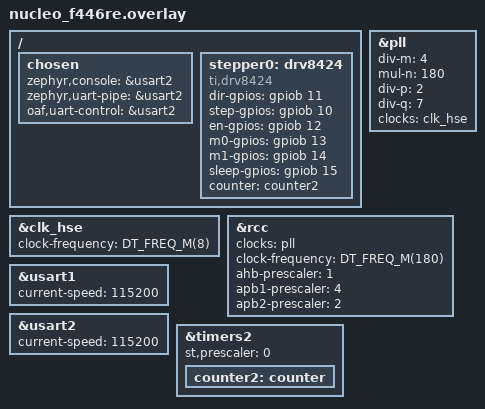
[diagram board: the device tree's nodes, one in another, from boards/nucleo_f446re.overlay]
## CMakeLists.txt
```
# SPDX-License-Identifier: Apache-2.0

cmake_minimum_required(VERSION 3.20.0)

list(APPEND EXTRA_CONF_FILE 
    "logging.conf"
)

find_package(Zephyr REQUIRED HINTS $ENV{ZEPHYR_BASE})
project(OpenAstroFirmware)

add_subdirectory(lib)

zephyr_syscall_include_directories(include)
zephyr_include_directories(include)

# print the value of LIB_INCLUDE_DIRS
# message(STATUS "LIB_INCLUDE_DIRS: ${LIB_INCLUDE_DIRS}")

include(CMakePrintHelpers)
cmake_print_variables(PROJECT_SOURCE_DIR)

# Add the source files to the target
file(GLOB_RECURSE APP_SOURCES "src/*.cpp" "src/*.c")
target_sources(app PRIVATE ${APP_SOURCES})
```

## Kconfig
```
module = FIRMWARE
module-str = firmware
source "subsys/logging/Kconfig.template.log_config"

rsource "lib/Kconfig"

rsource "src/mount/Kconfig"
rsource "src/processor/lx200/Kconfig"

menu "Zephyr"
source "Kconfig.zephyr"
endmenu
```

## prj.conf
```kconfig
# Disable zephyr log message at the beginning of the boot process
# CONFIG_BOOT_BANNER=n

# C++ support
CONFIG_CPP=y
CONFIG_STD_CPP20=y
CONFIG_REQUIRES_FULL_LIBCPP=y

# GPIO support
CONFIG_GPIO=y

# CONFIG_RING_BUFFER=y
# CONFIG_LX200=y

# CONFIG_TIMING_FUNCTIONS=y
CONFIG_MAIN_THREAD_PRIORITY=5

CONFIG_MAIN_STACK_SIZE=4096

# Stepper
CONFIG_POLL=y
CONFIG_COUNTER=y
CONFIG_STEPPER=y
CONFIG_STEP_DIR_STEPPER_COUNTER_TIMING=y

CONFIG_HEAP_MEM_POOL_SIZE=4096

# Thread analyzer
# CONFIG_THREAD_ANALYZER=y
# CONFIG_THREAD_ANALYZER_USE_PRINTK=y 
# CONFIG_THREAD_ANALYZER_AUTO=y
# CONFIG_THREAD_ANALYZER_AUTO_INTERVAL=5
```

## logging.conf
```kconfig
# Serial console
CONFIG_SERIAL=y
CONFIG_CONSOLE=y
CONFIG_CONSOLE_SUBSYS=y
CONFIG_CONSOLE_GETCHAR=y
CONFIG_CONSOLE_GETCHAR_BUFSIZE=64
CONFIG_CONSOLE_PUTCHAR_BUFSIZE=512
CONFIG_STDOUT_CONSOLE=y

# UART
CONFIG_UART_CONSOLE=y
CONFIG_UART_INTERRUPT_DRIVEN=y
CONFIG_UART_LINE_CTRL=y
CONFIG_UART_CONSOLE_LOG_LEVEL_DBG=y

CONFIG_LOG=y
CONFIG_LOG_BACKEND_UART=y
# CONFIG_LOG_MODE_DEFERRED=y
CONFIG_LOG_MODE_IMMEDIATE=y

# Enables runtime filtering for logging.
# This allows the logging level to be changed at runtime,
# providing flexibility for debugging and monitoring.
# CONFIG_LOG_RUNTIME_FILTERING=y
# CONFIG_LOG_BUFFER_SIZE=4096
# CONFIG_LOG_PRINTK=y
# CONFIG_LOG_PROCESS_TRIGGER_THRESHOLD=0
# CONFIG_LOG_TAG_MAX_LEN=8

CONFIG_LOG_THREAD_ID_PREFIX=y

# Enable thread analyzer in the logs
# CONFIG_THREAD_ANALYZER=y
# CONFIG_THREAD_ANALYZER_USE_PRINTK=y
# CONFIG_THREAD_ANALYZER_AUTO=y
# CONFIG_THREAD_ANALYZER_AUTO_INTERVAL=5

# Enable fault handling
# CONFIG_FAULT_DUMP=2
# CONFIG_EXCEPTION_STACK_TRACE=y
# CONFIG_DEBUG_COREDUMP=y 
# CONFIG_DEBUG_COREDUMP_BACKEND_LOGGING=y
# CONFIG_DEBUG_COREDUMP_MEMORY_DUMP_MIN=y

# Set log levels
# 0 - off
# 1 - error
# 2 - warning
# 3 - info
# 4 - debug

# Default log level (including zephyr)
CONFIG_LOG_DEFAULT_LEVEL=3

# OpenAstroFirmware log level. If multiple active, highest level wins.
# CONFIG_FIRMWARE_LOG_LEVEL_OFF=y # 0
# CONFIG_FIRMWARE_LOG_LEVEL_ERR=y # 1
# CONFIG_FIRMWARE_LOG_LEVEL_WRN=y # 2
# CONFIG_FIRMWARE_LOG_LEVEL_INF=y # 3 (default)
# CONFIG_FIRMWARE_LOG_LEVEL_DBG=y # 4

# Mount log level
# CONFIG_LOG_MOUNT_LEVEL=3
```

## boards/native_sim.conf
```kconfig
CONFIG_UART_CONSOLE=y

# Enable the native POSIX UART driver backend
CONFIG_UART_NATIVE_POSIX=y

# Console (logs) will be on stdout
# CONFIG_UART_NATIVE_PTY_0_ON_STDINOUT=y
# CONFIG_NATIVE_UART_0_ON_STDINOUT=y

# Enable UART for control (e.g. lx200)
CONFIG_UART_NATIVE_POSIX_PORT_1_ENABLE=y
```

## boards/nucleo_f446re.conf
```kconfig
CONFIG_SYS_CLOCK_HW_CYCLES_PER_SEC=180000000
CONFIG_CORTEX_M_SYSTICK=y

CONFIG_UART_USE_RUNTIME_CONFIGURE=y

# CONFIG_USB_DEVICE_STACK=y
# CONFIG_USB_DEVICE_INITIALIZE_AT_BOOT=n
# CONFIG_USB_DEVICE_VID=0x1209
# CONFIG_USB_DEVICE_PID=0x0AF0
# CONFIG_USB_DEVICE_PRODUCT="OpenAstroFirmware"
# CONFIG_USB_DEVICE_MANUFACTURER="OpenAstroTech"

# CONFIG_USB_CDC_ACM=y
# CONFIG_USB_CDC_ACM_RINGBUF_SIZE=512

# CONFIG_USB_COMPOSITE_DEVICE=y

# # CONFIG_USB_DEVICE_LOG_LEVEL_INF=y
# # CONFIG_USB_DRIVER_LOG_LEVEL_INF=y
# CONFIG_USB_CDC_ACM_LOG_LEVEL_OFF=y
```

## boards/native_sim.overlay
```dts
/ {
    chosen {
        zephyr,console = &uart0;
        // zephyr,shell-uart = &usart1;
        // zephyr,uart-mcumgr = &usart1;
        // zephyr,bt-mon-uart = &usart1;
        // zephyr,bt-c2h-uart = &usart1;
        // zephyr,log-backend-uart = &usart2;

        // zephyr,shell-uart = &usart1;
        // zephyr,uart-mcumgr = &usart1;
        oaf,uart-control = &uart1;
    };

    // uart {
    //     status = "okay";
    //     compatible = "zephyr,native-tty-uart";
    //     serial-port = "/tmp/tty1_device";
    //     current-speed = <115200>;
    // };
};

&uart0 {
    status = "okay";
    current-speed = <115200>;
};

// &uart1 {
    //     status = "okay";
    //     current-speed = <115200>;
// };

// &uart1 {
    //     status = "okay";
    //     current-speed = <115200>;
// };
```

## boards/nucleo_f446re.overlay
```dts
/ {
    chosen {
        zephyr,console = &usart2;
        zephyr,uart-pipe = &usart2;
        oaf,uart-control = &usart2;
    };

    stepper0: drv8424 {
        compatible = "ti,drv8424";
        status = "okay";

        #address-cells = <1>;
		#size-cells = <0>;
		#stepper-motor-cells = <0>;

        dir-gpios = <&gpiob 11 GPIO_ACTIVE_HIGH>;
        step-gpios = <&gpiob 10 GPIO_ACTIVE_HIGH>;
        en-gpios = <&gpiob 12 GPIO_ACTIVE_HIGH>;
        m0-gpios = <&gpiob 13 GPIO_ACTIVE_HIGH>;
        m1-gpios = <&gpiob 14 GPIO_ACTIVE_HIGH>;
        sleep-gpios = <&gpiob 15 GPIO_ACTIVE_HIGH>;
    
        counter = <&counter2>;
    };
};

&clk_hse {
    clock-frequency = <DT_FREQ_M(8)>;
};

&pll {
    div-m = <4>;
    mul-n = <180>;
    div-p = <2>;
    div-q = <7>;
    clocks = <&clk_hse>;
    status = "okay";
};

&rcc {
    clocks = <&pll>;
    clock-frequency = <DT_FREQ_M(180)>;
    ahb-prescaler = <1>;
    apb1-prescaler = <4>;
    apb2-prescaler = <2>;
};

&usart1 {
    status = "okay";
    current-speed = <115200>;
};

&usart2 {
    status = "okay";
    current-speed = <115200>;
};

&timers2 {
    status = "okay";
    st,prescaler = <0>;

    counter2: counter {
        status = "okay";
    };
};
```

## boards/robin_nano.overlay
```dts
/ {
    chosen {
        // we can't use cdc acm as console because it lacks required amount of cdc acm endpoints
        zephyr,console = &usart3; 
        oaf,uart-control = &cdc_acm_uart0;
    };
};

// Configuration for the CDC ACM UART
&zephyr_udc0 {
    cdc_acm_uart0: cdc_acm_uart0 {
        compatible = "zephyr,cdc-acm-uart";
    };
};
```

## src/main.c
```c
/*
 * Copyright (c) 2016 Open-RnD Sp. z o.o.
 * Copyright (c) 2020 Nordic Semiconductor ASA
 *
 * SPDX-License-Identifier: Apache-2.0
 */

#include <zephyr/kernel.h>
#include <zephyr/device.h>
#include <zephyr/drivers/gpio.h>
#include <zephyr/sys/util.h>
#include <zephyr/sys/printk.h>
#include <inttypes.h>

#include <lx200.h>

#define SLEEP_TIME_MS 1

/*
 * Get button configuration from the devicetree sw0 alias. This is mandatory.
 */
#define SW0_NODE DT_ALIAS(sw0)
#if !DT_NODE_HAS_STATUS(SW0_NODE, okay)
#error "Unsupported board: sw0 devicetree alias is not defined"
#endif
static const struct gpio_dt_spec button = GPIO_DT_SPEC_GET_OR(SW0_NODE, gpios, {0});
static struct gpio_callback button_cb_data;

/*
 * The led0 devicetree alias is optional. If present, we'll use it
 * to turn on the LED whenever the button is pressed.
 */
static struct gpio_dt_spec led = GPIO_DT_SPEC_GET_OR(DT_ALIAS(led0), gpios, {0});

void lx200_initialize()
{
	printk("Initializing LX200\n");
}

lx200_command_handler_t lx200_command_handler = {
	.lx200_initialize = lx200_initialize,
};

void button_pressed(const struct device *dev, struct gpio_callback *cb,
					uint32_t pins)
{
	lx200_parse_command(":g+#", 4, &lx200_command_handler);
	printk("Button pressed at %" PRIu32 "\n", k_cycle_get_32());
}

int main(void)
{
	int ret;

	if (!gpio_is_ready_dt(&button))
	{
		printk("Error: button device %s is not ready\n",
			   button.port->name);
		return 0;
	}

	ret = gpio_pin_configure_dt(&button, GPIO_INPUT);
	if (ret != 0)
	{
		printk("Error %d: failed to configure %s pin %d\n",
			   ret, button.port->name, button.pin);
		return 0;
	}

	ret = gpio_pin_interrupt_configure_dt(&button,
										  GPIO_INT_EDGE_TO_ACTIVE);
	if (ret != 0)
	{
		printk("Error %d: failed to configure interrupt on %s pin %d\n",
			   ret, button.port->name, button.pin);
		return 0;
	}

	gpio_init_callback(&button_cb_data, button_pressed, BIT(button.pin));
	gpio_add_callback(button.port, &button_cb_data);
	printk("Set up button at %s pin %d\n", button.port->name, button.pin);

	if (led.port && !gpio_is_ready_dt(&led))
	{
		printk("Error %d: LED device %s is not ready; ignoring it\n",
			   ret, led.port->name);
		led.port = NULL;
	}
	if (led.port)
	{
		ret = gpio_pin_configure_dt(&led, GPIO_OUTPUT);
		if (ret != 0)
		{
			printk("Error %d: failed to configure LED device %s pin %d\n",
				   ret, led.port->name, led.pin);
			led.port = NULL;
		}
		else
		{
			printk("Set up LED at %s pin %d\n", led.port->name, led.pin);
		}
	}

	printk("Press the button\n");
	if (led.port)
	{
		while (1)
		{
			/* If we have an LED, match its state to the button's. */
			int val = gpio_pin_get_dt(&button);

			if (val >= 0)
			{
				gpio_pin_set_dt(&led, val);
			}
			k_msleep(SLEEP_TIME_MS);
		}
	}
	return 0;
}
```

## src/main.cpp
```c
/*
 * Copyright (c) 2016 Open-RnD Sp. z o.o.
 * Copyright (c) 2020 Nordic Semiconductor ASA
 *
 * SPDX-License-Identifier: Apache-2.0
 */

#include <inttypes.h>

#include <zephyr/device.h>
#include <zephyr/drivers/gpio.h>
#include <zephyr/drivers/uart.h>
#include <zephyr/kernel.h>
#include <zephyr/logging/log.h>
#include <zephyr/usb/usb_device.h>

#include "HardwareConfiguration.hpp"

#include <mount/Mount.hpp>
#include <mount/MountWorker.hpp>

#include "device/uart/InterruptUART.hpp"
#include "device/uart/PollingUART.hpp"
#include "processor/lx200/Lx200Processor.hpp"

LOG_MODULE_REGISTER(main, CONFIG_FIRMWARE_LOG_LEVEL);

Mount mount;
MountWorker mount_worker(mount);

K_MSGQ_DEFINE(uart_msgq, sizeof(uint8_t), CONFIG_LX200_MESSAGE_BUFFER_SIZE, 1);

Lx200Processor lx200_processor(&uart_msgq, mount_worker);

K_THREAD_DEFINE(
	lx200,							 // Thread identifier
	CONFIG_LX200_STACK_SIZE,		 // Stack size in bytes
	Lx200Processor::thread_function, // Entry point function for the thread
	&lx200_processor, NULL, NULL,	 // Arguments passed to the thread function (arg1, arg2, arg3)
	10,								 // Thread priority (lower number = higher priority)
	0,								 // Thread options (0 = no special options)
	0								 // Delay before starting the thread (0 = start immediately)
);

int main(void)
{
	LOG_INF("Starting OpenAstroFirmware");
	LOG_INF("Board: %s", CONFIG_BOARD);
	LOG_INF("MCU Frequency: %u Hz", sys_clock_hw_cycles_per_sec());

#ifdef CONFIG_USB_DEVICE_STACK
	if (usb_enable(NULL) != 0)
	{
		LOG_ERR("Failed to enable USB");
		return 0;
	}
#endif

	if (!device_is_ready(dt::uart_control_dev))
	{
		LOG_ERR("Control UART device not ready\n");
		return ENODEV;
	}

	struct uart_config uart_cfg;
	if (uart_config_get(dt::uart_control_dev, &uart_cfg))
	{
		LOG_ERR("Failed to get control UART configuration");
	}
	else
	{
		LOG_INF("Control UART Baud Rate: %d", uart_cfg.baudrate);
	}

	devices::uart::InterruptUART isr_uart(dt::uart_control_dev, &uart_msgq);
	isr_uart.enable();

	// devices::uart::PollingUART poll_uart(dt::uart_control_dev, &uart_msgq);
	// poll_uart.enable();

	while (1)
	{
		k_sleep(K_MSEC(1000));
	}

	return 0;
}
```

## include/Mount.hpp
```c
#pragma once

#include <zephyr/zbus/zbus.h>

class Mount {
private:
public:
    Mount();  // Constructor
    ~Mount(); // Destructor

    /**
     * @brief Initialize the mount
     */
    void initialize();

    /**
     * @brief Set the Target Dec object
     * 
     * @param d degrees
     * @param m minutes
     * @param s seconds
     */
    void setTargetDec(int d, int m, int s);

    /**
     * @brief Set the Target Ra object
     * 
     * @param h hours
     * @param m minutes
     * @param s seconds
     */
    void setTargetRa(int h, int m, int s);
};

struct MountControlCommand
{
    size_t type;
    /* data */
};

ZBUS_CHAN_DECLARE(mount_control_chan);
```

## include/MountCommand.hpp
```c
#pragma once

#include <cstddef>
#include <atomic>

enum MountCommandType
{
    InitializeMount,
    SetTargetRA
};

struct MountCommand
{
    const MountCommandType type;
    const size_t corr_id;

    MountCommand(const MountCommandType type) : corr_id(counter++), type(type) {}

    static std::atomic<unsigned long> counter;
};

struct InitializeMountCommand : public MountCommand
{
    InitializeMountCommand() : MountCommand(InitializeMount) {}
};

struct SetTargetRACommand : public MountCommand
{
    const unsigned int hh;
    const unsigned int mm;
    const unsigned int ss;

    SetTargetRACommand(unsigned int hh, unsigned int mm, unsigned int ss) : MountCommand(SetTargetRA), hh(hh), mm(mm), ss(ss) {}
};
```

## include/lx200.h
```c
#ifndef FIRMWARE_LIB_LX200_H
#define FIRMWARE_LIB_LX200_H

/* Alignment Commands */
// :Aa#    Start Telescope Automatic Alignment Sequence [LX200GPS only]
// :AL#    Sets telescope to Land alignment mode
// :AP#    Sets telescope to Polar alignment mode
// :AA#    Sets telescope the AltAz alignment mode

/* Active Backlash Compensation */
// :$BAdd# Set Altitude/Dec Antibacklash
// :$BZdd# Set Azimuth/RA Antibacklash

/* Reticule/Accessory Control */
// :B+#    Increase reticule Brightness
// :B-#    Decrease Reticule Brightness
// :B<n>#  Set Reticle flash rate to <n> (an ASCII expressed number)
// :BDn#   Set Reticule Duty flash duty cycle to <n> (an ASCII expressed digit) [LX200 GPS Only]

/* Sync Control */
// :CL#    Synchonize the telescope with the current Selenographic coordinates.
// :CM#    Synchronizes the telescope's position with the currently selected database object's coordinates.

/* Distance Bars */
// :D#     Requests a string of bars indicating the distance to the current library object.

/* Fan Command */
// :f+#    LX 16”– Turn on the tube exhaust fan, LX200GPS – Turn on power to accessor panel
// :f-#    LX 16”– Turn off tube exhaust fan, LX200GPS - Turn off power to accessory panel
// :fT#    LX200GPS – Return Optical Tube Assembly Temperature

/* Focuser Control */
// :F+#    Start Focuser moving inward (toward objective)
// :F-#    Start Focuser moving outward (away from objective)
// :FQ#    Halt Focuser Motion
// :FF#    Set Focus speed to fastest setting
// :FS#    Set Focus speed to slowest setting
// :F<n>#  Autostar & LX200GPS – set focuser speed to <n> where <n> is an ASCII digit 1..4

/* GPS/Magnetometer commands */
// :g+#    LX200GPS Only - Turn on GPS
// :g-#    LX200GPS Only - Turn off GPS
// :gps#   LX200GPS Only – Turns on NMEA GPS data stream.
// :gT#    Powers up the GPS and updates the system time from the GPS stream.

/* Get Telescope Information */
// :G0#    Get Alignment Menu Entry 0 [LX200 legacy command]
// :G1#    Get Alignment Menu Entry 0 [LX200 legacy command]
// :G2#    Get Alignment Menu Entry 0 [LX200 legacy command]
// :GA#    Get Telescope Altitude
// :Ga#    Get Local Telescope Time In 12 Hour Format
// :Gb#    Get Browse Brighter Magnitude Limit
// :GC#    Get current date.
// :Gc#    Get Calendar Format
// :GD#    Get Telescope Declination.
// :Gd#    Get Currently Selected Object/Target Declination
// :GF#    Get Find Field Diameter
// :Gf#    Get Browse Faint Magnitude Limit
// :GG#    Get UTC offset time
// :Gg#    Get Current Site Longitude
// :Gh#    Get High Limit
// :GL#    Get Local Time in 24 hour format
// :Gl#    Get Larger Size Limit
// :GM#    Get Site 1 Name
// :GN#    Get Site 2 Name
// :GO#    Get Site 3 Name
// :GP#    Get Site 4 Name
// :Go#    Get Lower Limit
// :Gq#    Get Minimum Quality For Find Operation
// :GR#    Get Telescope RA
// :Gr#    Get current/target object RA
// :GS#    Get the Sidereal Time
// :Gs#    Get Smaller Size Limit
// :GT#    Get tracking rate
// :Gt#    Get Current Site Latitude
// :GVD#   Get Telescope Firmware Date
// :GVN#   Get Telescope Firmware Number
// :GVP#   Get Telescope Product Name
// :GVT#   Get Telescope Firmware Time
// :Gy#    Get deepsky object search string
// :GZ#    Get telescope azimuth

/* Home Position Commands */
// :hS#    LX200GPS and LX 16” Seeks Home Position and stores the encoder values
// :hF#    LX200GPS and LX 16” Seeks the Home Position of the scope and sets/aligns
// :hN#    LX200GPS only: Sleep Telescope.
// :hP#    Autostar, LX200GPS and LX 16”Slew to Park Position
// :hW#    LX200 GPS Only: Wake up sleeping telescope.
// :h?#    Autostar, LX200GPS and LX 16” Query Home Status

/* Time Format Command */
// :H#     Toggle Between 24 and 12 hour time format

/* Initialize Telescope Command */
// :I#     LX200 GPS Only - Causes the telescope to cease current operations and restart at its power on initialization.

/* Object Library Commands */
// :LB#    Find previous object and set it as the current target object.
// :LCNNNN# Set current target object to deep sky catalog object number NNNN
// :LF#    Find Object using the current Size, Type, Upper limit, lower limit and Quality constraints and set it as current target object.
// :Lf#    Identify object in current field.
// :LI#    Get Object Information
// :LMNNNN# Set current target object to Messier Object NNNN, an ASCII expressed decimal number.
// :LN#    Find next deep sky target object subject to the current constraints.
// :LoD#   Select deep sky Library where D specifies
// :LsD#   Select star catalog D, an ASCII integer where D specifies
// :LSNNNN# Select star NNNN as the current target object from the currently selected catalog

/* Telescope Movement Commands */
// :MA#    Autostar, LX 16”, LX200GPS – Slew to target Alt and Az
// :Me#    Move Telescope East at current slew rate
// :Mn#    Move Telescope North at current slew rate
// :Ms#    Move Telescope South at current slew rate
// :Mw#    Move Telescope West at current slew rate
// :MS#    Slew to Target Object

/* High Precision Toggle */
// :P#     Toggles High Precision Pointing.

/* Smart Drive Control */
// $Q#     Toggles Smart Drive PEC on and off for both axis
// :$QA+   Enable Dec/Alt PEC [LX200gps only]
// :$QA-   Enable Dec/Alt PEC [LX200gps only]
// :$QZ+   Enable RA/AZ PEC compensation [LX200gps only]
// :$QZ-   Disable RA/AZ PEC Compensation [LX200gps only]

/* Movement Commands */
// :Q#     Halt all current slewing
// :Qe#    Halt eastward Slews
// :Qn#    Halt northward Slews
// :Qs#    Halt southward Slews
// :Qw#    Halt westward Slews

/* Field Derotator Commands */
// :r+#    Turn on Field Derotator [LX 16” and LX200GPS]
// :r-#    Turn off Field Derotator, halt slew in progress. [Lx 16” and LX200GPS]

/* Slew Rate Commands */
// :RC#    Set Slew rate to Centering rate (2nd slowest)
// :RG#    Set Slew rate to Guiding Rate (slowest)
// :RM#    Set Slew rate to Find Rate (2nd Fastest)
// :RS#    Set Slew rate to max (fastest)
// :RADD.D# Set RA/Azimuth Slew rate to DD.D degrees per second [LX200GPS Only]
// :REDD.D# Set Dec/Elevation Slew rate to DD.D degrees per second [LX200GPS only]
// :RgSS.S# Set guide rate to +/- SS.S to arc seconds per second.

/* Telescope Set Commands */
// :SasDD*MM# Set target object altitude to sDD*MM# or sDD*MM’SS# [LX 16”, Autostar, LX200GPS]
// :SbsMM.M#  Set Brighter limit to the ASCII decimal magnitude string. SMM.M
// :SBn#      Set Baud Rate n, where n is an ASCII digit (1..9)
// :SCMM/DD/YY# Change Handbox Date to MM/DD/YY
// :SdsDD*MM# Set target object declination to sDD*MM

// meade lx200 command handler
typedef struct
{
    /**
     * @brief LX200 GPS Only - Causes the telescope to cease current operations and restart at its power on initialization.
     */
    void (*lx200_initialize)();
} lx200_command_handler_t;

/**
 * @brief Parse the command and call the appropriate handler function
 */
void lx200_parse_command(char *command, int cnt, lx200_command_handler_t *handler);

#endif
```

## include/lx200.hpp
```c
#ifndef FIRMWARE_LIB_LX200_H
#define FIRMWARE_LIB_LX200_H

/* Alignment Commands */
// :Aa#    Start Telescope Automatic Alignment Sequence [LX200GPS only]
// :AL#    Sets telescope to Land alignment mode
// :AP#    Sets telescope to Polar alignment mode
// :AA#    Sets telescope the AltAz alignment mode

/* Active Backlash Compensation */
// :$BAdd# Set Altitude/Dec Antibacklash
// :$BZdd# Set Azimuth/RA Antibacklash

/* Reticule/Accessory Control */
// :B+#    Increase reticule Brightness
// :B-#    Decrease Reticule Brightness
// :B<n>#  Set Reticle flash rate to <n> (an ASCII expressed number)
// :BDn#   Set Reticule Duty flash duty cycle to <n> (an ASCII expressed digit) [LX200 GPS Only]

/* Sync Control */
// :CL#    Synchonize the telescope with the current Selenographic coordinates.
// :CM#    Synchronizes the telescope's position with the currently selected database object's coordinates.

/* Distance Bars */
// :D#     Requests a string of bars indicating the distance to the current library object.

/* Fan Command */
// :f+#    LX 16”– Turn on the tube exhaust fan, LX200GPS – Turn on power to accessor panel
// :f-#    LX 16”– Turn off tube exhaust fan, LX200GPS - Turn off power to accessory panel
// :fT#    LX200GPS – Return Optical Tube Assembly Temperature

/* Focuser Control */
// :F+#    Start Focuser moving inward (toward objective)
// :F-#    Start Focuser moving outward (away from objective)
// :FQ#    Halt Focuser Motion
// :FF#    Set Focus speed to fastest setting
// :FS#    Set Focus speed to slowest setting
// :F<n>#  Autostar & LX200GPS – set focuser speed to <n> where <n> is an ASCII digit 1..4

/* GPS/Magnetometer commands */
// :g+#    LX200GPS Only - Turn on GPS
// :g-#    LX200GPS Only - Turn off GPS
// :gps#   LX200GPS Only – Turns on NMEA GPS data stream.
// :gT#    Powers up the GPS and updates the system time from the GPS stream.

/* Get Telescope Information */
// :G0#    Get Alignment Menu Entry 0 [LX200 legacy command]
// :G1#    Get Alignment Menu Entry 0 [LX200 legacy command]
// :G2#    Get Alignment Menu Entry 0 [LX200 legacy command]
// :GA#    Get Telescope Altitude
// :Ga#    Get Local Telescope Time In 12 Hour Format
// :Gb#    Get Browse Brighter Magnitude Limit
// :GC#    Get current date.
// :Gc#    Get Calendar Format
// :GD#    Get Telescope Declination.
// :Gd#    Get Currently Selected Object/Target Declination
// :GF#    Get Find Field Diameter
// :Gf#    Get Browse Faint Magnitude Limit
// :GG#    Get UTC offset time
// :Gg#    Get Current Site Longitude
// :Gh#    Get High Limit
// :GL#    Get Local Time in 24 hour format
// :Gl#    Get Larger Size Limit
// :GM#    Get Site 1 Name
// :GN#    Get Site 2 Name
// :GO#    Get Site 3 Name
// :GP#    Get Site 4 Name
// :Go#    Get Lower Limit
// :Gq#    Get Minimum Quality For Find Operation
// :GR#    Get Telescope RA
// :Gr#    Get current/target object RA
// :GS#    Get the Sidereal Time
// :Gs#    Get Smaller Size Limit
// :GT#    Get tracking rate
// :Gt#    Get Current Site Latitude
// :GVD#   Get Telescope Firmware Date
// :GVN#   Get Telescope Firmware Number
// :GVP#   Get Telescope Product Name
// :GVT#   Get Telescope Firmware Time
// :Gy#    Get deepsky object search string
// :GZ#    Get telescope azimuth

/* Home Position Commands */
// :hS#    LX200GPS and LX 16” Seeks Home Position and stores the encoder values
// :hF#    LX200GPS and LX 16” Seeks the Home Position of the scope and sets/aligns
// :hN#    LX200GPS only: Sleep Telescope.
// :hP#    Autostar, LX200GPS and LX 16”Slew to Park Position
// :hW#    LX200 GPS Only: Wake up sleeping telescope.
// :h?#    Autostar, LX200GPS and LX 16” Query Home Status

/* Time Format Command */
// :H#     Toggle Between 24 and 12 hour time format

/* Initialize Telescope Command */
// :I#     LX200 GPS Only - Causes the telescope to cease current operations and restart at its power on initialization.

/* Object Library Commands */
// :LB#    Find previous object and set it as the current target object.
// :LCNNNN# Set current target object to deep sky catalog object number NNNN
// :LF#    Find Object using the current Size, Type, Upper limit, lower limit and Quality constraints and set it as current target object.
// :Lf#    Identify object in current field.
// :LI#    Get Object Information
// :LMNNNN# Set current target object to Messier Object NNNN, an ASCII expressed decimal number.
// :LN#    Find next deep sky target object subject to the current constraints.
// :LoD#   Select deep sky Library where D specifies
// :LsD#   Select star catalog D, an ASCII integer where D specifies
// :LSNNNN# Select star NNNN as the current target object from the currently selected catalog

/* Telescope Movement Commands */
// :MA#    Autostar, LX 16”, LX200GPS – Slew to target Alt and Az
// :Me#    Move Telescope East at current slew rate
// :Mn#    Move Telescope North at current slew rate
// :Ms#    Move Telescope South at current slew rate
// :Mw#    Move Telescope West at current slew rate
// :MS#    Slew to Target Object

/* High Precision Toggle */
// :P#     Toggles High Precision Pointing.

/* Smart Drive Control */
// $Q#     Toggles Smart Drive PEC on and off for both axis
// :$QA+   Enable Dec/Alt PEC [LX200gps only]
// :$QA-   Enable Dec/Alt PEC [LX200gps only]
// :$QZ+   Enable RA/AZ PEC compensation [LX200gps only]
// :$QZ-   Disable RA/AZ PEC Compensation [LX200gps only]

/* Movement Commands */
// :Q#     Halt all current slewing
// :Qe#    Halt eastward Slews
// :Qn#    Halt northward Slews
// :Qs#    Halt southward Slews
// :Qw#    Halt westward Slews

/* Field Derotator Commands */
// :r+#    Turn on Field Derotator [LX 16” and LX200GPS]
// :r-#    Turn off Field Derotator, halt slew in progress. [Lx 16” and LX200GPS]

/* Slew Rate Commands */
// :RC#    Set Slew rate to Centering rate (2nd slowest)
// :RG#    Set Slew rate to Guiding Rate (slowest)
// :RM#    Set Slew rate to Find Rate (2nd Fastest)
// :RS#    Set Slew rate to max (fastest)
// :RADD.D# Set RA/Azimuth Slew rate to DD.D degrees per second [LX200GPS Only]
// :REDD.D# Set Dec/Elevation Slew rate to DD.D degrees per second [LX200GPS only]
// :RgSS.S# Set guide rate to +/- SS.S to arc seconds per second.

/* Telescope Set Commands */
// :SasDD*MM# Set target object altitude to sDD*MM# or sDD*MM’SS# [LX 16”, Autostar, LX200GPS]
// :SbsMM.M#  Set Brighter limit to the ASCII decimal magnitude string. SMM.M
// :SBn#      Set Baud Rate n, where n is an ASCII digit (1..9)
// :SCMM/DD/YY# Change Handbox Date to MM/DD/YY
// :SdsDD*MM# Set target object declination to sDD*MM

class MeadeLX200CommandParser
{
private:
    /* data */
public:
    MeadeLX200CommandParser();
    ~MeadeLX200CommandParser();
};

MeadeLX200CommandParser::MeadeLX200CommandParser()
{
}

MeadeLX200CommandParser::~MeadeLX200CommandParser()
{
}


#endif
```

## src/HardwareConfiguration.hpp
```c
#include <zephyr/device.h>

/**
 * @brief Device tree configuration namespace
 */
namespace dt
{
/**
 * Get button configuration from the devicetree sw0 alias. E.g. this is the user button on a nucleo board.
 */
#if DT_NODE_HAS_STATUS(DT_ALIAS(sw0), okay)
#define SW0_BUTTON 1
    static const struct gpio_dt_spec sw0_button_spec = GPIO_DT_SPEC_GET_OR(DT_ALIAS(sw0), gpios, {0});
#else
#define SW0_BUTTON 0
#endif /* DT_NODE_HAS_STATUS(DT_ALIAS(sw0), okay) */

/**
 * Get UART configuration from the devicetree chosen node. This is the UART used for control commands.
 */
#if DT_NODE_HAS_STATUS(DT_CHOSEN(oaf_uart_control), okay)
    static const struct device *uart_control_dev = DEVICE_DT_GET(DT_CHOSEN(oaf_uart_control));
#endif /* DT_NODE_HAS_STATUS(DT_CHOSEN(oaf_uart_control), okay) */

}
```

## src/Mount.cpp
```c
#include <Mount.hpp>

#include <zephyr/kernel.h>
#include <zephyr/logging/log.h>
LOG_MODULE_REGISTER(Mount);

Mount::Mount() {
    LOG_DBG("creating Mount");
    // Constructor implementation
}

Mount::~Mount() {
    // Destructor implementation
}

void Mount::initialize() {

    LOG_INF("Initializing the mount");
}

void Mount::setTargetDec(int d, int m, int s) {
    LOG_INF("Setting the target DEC to %d*%d'%d\"", d, m, s);
}

void Mount::setTargetRa(int h, int m, int s) {
    LOG_INF("Setting the target RA to %d:%d:%d", h, m, s);
}
```

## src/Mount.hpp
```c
#ifndef MOUNT_H
#define MOUNT_H

class Mount {
private:
public:
    Mount();  // Constructor
    ~Mount(); // Destructor

    void initialize(); // Method to initialize the mount
    void moveTo(double azimuth, double altitude); // Method to move the mount
    void stop(); // Method to stop the mount
};

#endif // MOUNT_H
```
